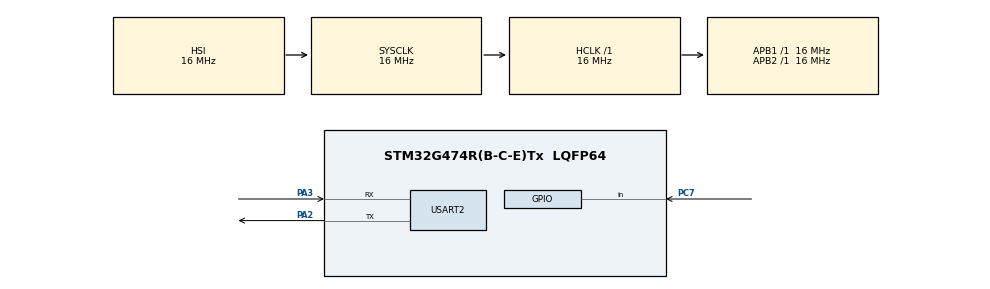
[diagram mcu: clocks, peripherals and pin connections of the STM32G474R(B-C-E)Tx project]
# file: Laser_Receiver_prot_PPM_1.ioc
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Mcu.Family=STM32G4
Mcu.Name=STM32G474R(B-C-E)Tx
Mcu.Package=LQFP64
NVIC.PriorityGroup=NVIC_PRIORITYGROUP_4
NVIC.USART2_IRQn=true\:0\:0\:false\:false\:true\:true\:true\:true
PA2.Mode=Asynchronous
PA2.Signal=USART2_TX
PA3.Mode=Asynchronous
PA3.Signal=USART2_RX
PC7.Signal=GPIO_Input
ProjectManager.HeapSize=0x200
ProjectManager.StackSize=0x400
ProjectManager.TargetToolchain=STM32CubeIDE
RCC.AHBFreq_Value=16000000
RCC.APB1Freq_Value=16000000
RCC.APB1TimFreq_Value=16000000
RCC.APB2Freq_Value=16000000
RCC.APB2TimFreq_Value=16000000
RCC.CortexFreq_Value=16000000
RCC.EXTERNAL_CLOCK_VALUE=12288000
RCC.HCLKFreq_Value=16000000
RCC.HSE_VALUE=8000000
RCC.HSI48_VALUE=48000000
RCC.HSI_VALUE=16000000
RCC.LSE_VALUE=32768
RCC.SYSCLKFreq_VALUE=16000000
RCC.USBFreq_Value=64000000
RCC.VCOOutputFreq_Value=128000000
USART2.VirtualMode-Asynchronous=VM_ASYNC
VP_SYS_VS_DBSignals.Mode=DisableDeadBatterySignals
board=custom

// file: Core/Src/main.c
/* USER CODE BEGIN Header */
/**
  ******************************************************************************
  * @file           : main.c
  * @brief          : Main program body
  ******************************************************************************
  * @attention
  *
  * Copyright (c) 2025 STMicroelectronics.
  * All rights reserved.
  *
  * This software is licensed under terms that can be found in the LICENSE file
  * in the root directory of this software component.
  * If no LICENSE file comes with this software, it is provided AS-IS.
  *
  ******************************************************************************
  */
/* USER CODE END Header */
#include "main.h"
#include "stdio.h"

UART_HandleTypeDef huart2;

/* USER CODE BEGIN PV */
//double start = 0;
//double cur_time = 0;

uint8_t cur_light = 0;
uint8_t zero_count = 0;
uint8_t cur_sum = 0;
uint8_t rec_buff[108];
uint8_t rec_sums[108];

char tx_buffer[32];

uint32_t start, stop, elapsed;
double elapsedtime;
/* USER CODE END PV */

void SystemClock_Config(void);
static void MX_GPIO_Init(void);
static void MX_USART2_UART_Init(void);

int main(void)
{

  /* MCU Configuration--------------------------------------------------------*/

  /* Reset of all peripherals, Initializes the Flash interface and the Systick. */
  HAL_Init();

  /* Configure the system clock */
  SystemClock_Config();

  /* Initialize all configured peripherals */
  MX_GPIO_Init();
  MX_USART2_UART_Init();
  /* USER CODE BEGIN 2 */
  CoreDebug->DEMCR |= CoreDebug_DEMCR_TRCENA_Msk;
  DWT->CYCCNT = 0;
  DWT->CTRL |= DWT_CTRL_CYCCNTENA_Msk;

  TIM2->CCR3 = 500;
  //HAL_TIM_PWM_Start(&htim2, TIM_CHANNEL_3);
  start = DWT->CYCCNT;
  /* USER CODE END 2 */

  /* Infinite loop */
  /* USER CODE BEGIN WHILE */
  while (1)
  {
	  HAL_UART_Transmit(&huart2, (uint8_t*)"\n\rAwaiting the message\n\r", 24, 5);
	  while(cur_light != 1){
		  cur_light = HAL_GPIO_ReadPin(GPIOC, GPIO_PIN_7);
		  //HAL_Delay(0.1);
	  }
	  //HAL_UART_Transmit(&huart2, (uint8_t*)"\n\rReceiving started\n\r", 24, 1);
	  HAL_Delay(11);
	  int ind = 0;
	  int i = 0;
	  while(zero_count < 4){
		  zero_count = 0;
		  for(int k = 0; k < 4; k++){
			  start = DWT->CYCCNT;
			  stop = DWT->CYCCNT;
			  elapsed = stop - start;
			  elapsedtime = (1.0 / (double)SystemCoreClock) * (double)elapsed;
			  cur_sum = 0;
			  while(elapsedtime < 0.01063){
				  cur_light = HAL_GPIO_ReadPin(GPIOC, GPIO_PIN_7);
				  if (cur_light){
					  cur_sum++;
					  //HAL_UART_Transmit(&huart2, (uint8_t*)"1", 1, 5);
					  //sprintf(tx_buffer, " %f\n\r", elapsedtime);
					  //HAL_UART_Transmit(&huart2, (uint8_t*)tx_buffer, 32, 5);
				  }else{
					  //HAL_UART_Transmit(&huart2, (uint8_t*)"0", 1, 5);
					  //sprintf(tx_buffer, " %f\n\r", elapsedtime);
					  //HAL_UART_Transmit(&huart2, (uint8_t*)tx_buffer, 32, 5);
				  }
				  stop = DWT->CYCCNT;
				  elapsed = stop - start;
				  elapsedtime = (1.0 / (double)SystemCoreClock) * (double)elapsed;
			  }
			  rec_sums[ind++] = cur_sum;
			  if(cur_sum > 120){
				  if(k == 0){
					  rec_buff[i++] = 0;
					  rec_buff[i++] = 0;
				  }else if(k == 1){
					  rec_buff[i++] = 0;
					  rec_buff[i++] = 1;
				  }else if(k == 2){
					  rec_buff[i++] = 1;
					  rec_buff[i++] = 0;
				  }else if(k == 3){
					  rec_buff[i++] = 1;
					  rec_buff[i++] = 1;
				  }
			  }else{
				  zero_count++;
			  }
			  //rec_buff[i] = cur_sum;
			  //i++;
		  }
	  }
	  zero_count = 0;
	  int j = 0;
	  while(zero_count < 8){
		  sprintf(tx_buffer, "%d", rec_buff[j]);
		  HAL_UART_Transmit(&huart2, (uint8_t*)tx_buffer, 32, 1);
		  if(rec_buff[j] == 0){
			  zero_count++;
		  }else{
			  zero_count = 0;
		  }
		  rec_buff[j] = 0;
		  j++;
	  }
	  HAL_UART_Transmit(&huart2, (uint8_t*)"\n\r", 2, 5);
	  zero_count = 0;
	  j = 0;
	  while(zero_count < 8){
		  sprintf(tx_buffer, "%d ", rec_sums[j]);
		  HAL_UART_Transmit(&huart2, (uint8_t*)tx_buffer, 32, 1);
		  if(rec_sums[j] == 0){
			  zero_count++;
		  }else{
			  zero_count = 0;
		  }
		  j++;
	  }
	  cur_light = 0;
	  zero_count = 0;
	  /*
	  cur_light = HAL_GPIO_ReadPin(GPIOC, GPIO_PIN_7);
	  stop = DWT->CYCCNT;
	  elapsed = stop - start;
	  elapsedtime = (1.0 / (double)SystemCoreClock) * (double)elapsed; // time in seconds
	  if (cur_light){
		  HAL_UART_Transmit(&huart2, (uint8_t*)"1 ", 2, 5);
	  }else{
		  HAL_UART_Transmit(&huart2, (uint8_t*)"0 ", 2, 5);
	  }
	  sprintf(tx_buffer, "%f", elapsedtime);
	  HAL_UART_Transmit(&huart2, (uint8_t*)tx_buffer, 32, 5);
	  HAL_UART_Transmit(&huart2, (uint8_t*)"\n\r", 2, 5);
	  HAL_Delay(5);*/
    /* USER CODE END WHILE */

  }
}

void SystemClock_Config(void)
{
  RCC_OscInitTypeDef RCC_OscInitStruct = {0};
  RCC_ClkInitTypeDef RCC_ClkInitStruct = {0};

  /** Configure the main internal regulator output voltage
  */
  HAL_PWREx_ControlVoltageScaling(PWR_REGULATOR_VOLTAGE_SCALE1);

  /** Initializes the RCC Oscillators according to the specified parameters
  * in the RCC_OscInitTypeDef structure.
  */
  RCC_OscInitStruct.OscillatorType = RCC_OSCILLATORTYPE_HSI;
  RCC_OscInitStruct.HSIState = RCC_HSI_ON;
  RCC_OscInitStruct.HSICalibrationValue = RCC_HSICALIBRATION_DEFAULT;
  RCC_OscInitStruct.PLL.PLLState = RCC_PLL_NONE;
  if (HAL_RCC_OscConfig(&RCC_OscInitStruct) != HAL_OK)
  {
    Error_Handler();
  }

  /** Initializes the CPU, AHB and APB buses clocks
  */
  RCC_ClkInitStruct.ClockType = RCC_CLOCKTYPE_HCLK|RCC_CLOCKTYPE_SYSCLK
                              |RCC_CLOCKTYPE_PCLK1|RCC_CLOCKTYPE_PCLK2;
  RCC_ClkInitStruct.SYSCLKSource = RCC_SYSCLKSOURCE_HSI;
  RCC_ClkInitStruct.AHBCLKDivider = RCC_SYSCLK_DIV1;
  RCC_ClkInitStruct.APB1CLKDivider = RCC_HCLK_DIV1;
  RCC_ClkInitStruct.APB2CLKDivider = RCC_HCLK_DIV1;

  if (HAL_RCC_ClockConfig(&RCC_ClkInitStruct, FLASH_LATENCY_0) != HAL_OK)
  {
    Error_Handler();
  }
}

static void MX_USART2_UART_Init(void)
{

  huart2.Instance = USART2;
  huart2.Init.BaudRate = 115200;
  huart2.Init.WordLength = UART_WORDLENGTH_8B;
  huart2.Init.StopBits = UART_STOPBITS_1;
  huart2.Init.Parity = UART_PARITY_NONE;
  huart2.Init.Mode = UART_MODE_TX_RX;
  huart2.Init.HwFlowCtl = UART_HWCONTROL_NONE;
  huart2.Init.OverSampling = UART_OVERSAMPLING_16;
  huart2.Init.OneBitSampling = UART_ONE_BIT_SAMPLE_DISABLE;
  huart2.Init.ClockPrescaler = UART_PRESCALER_DIV1;
  huart2.AdvancedInit.AdvFeatureInit = UART_ADVFEATURE_NO_INIT;
  if (HAL_UART_Init(&huart2) != HAL_OK)
  {
    Error_Handler();
  }
  if (HAL_UARTEx_SetTxFifoThreshold(&huart2, UART_TXFIFO_THRESHOLD_1_8) != HAL_OK)
  {
    Error_Handler();
  }
  if (HAL_UARTEx_SetRxFifoThreshold(&huart2, UART_RXFIFO_THRESHOLD_1_8) != HAL_OK)
  {
    Error_Handler();
  }
  if (HAL_UARTEx_DisableFifoMode(&huart2) != HAL_OK)
  {
    Error_Handler();
  }

}

static void MX_GPIO_Init(void)
{
  GPIO_InitTypeDef GPIO_InitStruct = {0};

  /* GPIO Ports Clock Enable */
  __HAL_RCC_GPIOA_CLK_ENABLE();
  __HAL_RCC_GPIOC_CLK_ENABLE();

  /*Configure GPIO pin : PC7 */
  GPIO_InitStruct.Pin = GPIO_PIN_7;
  GPIO_InitStruct.Mode = GPIO_MODE_INPUT;
  GPIO_InitStruct.Pull = GPIO_NOPULL;
  HAL_GPIO_Init(GPIOC, &GPIO_InitStruct);

}

void Error_Handler(void)
{
  __disable_irq();
  while (1)
  {
  }
}
